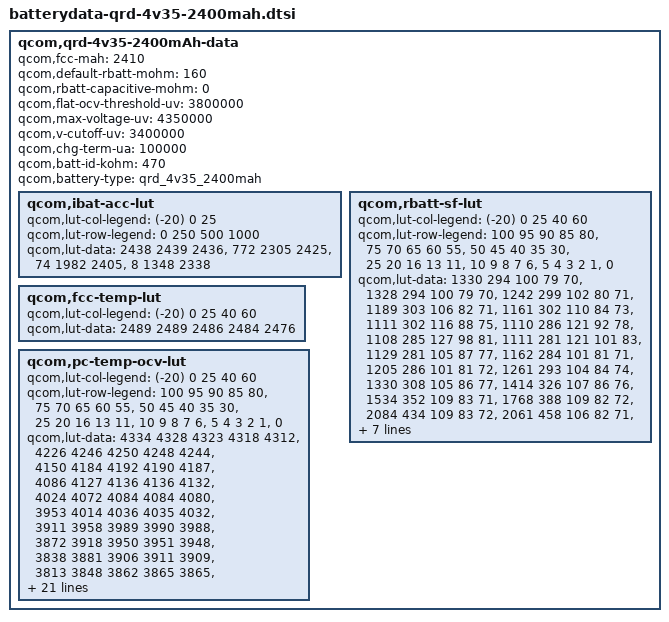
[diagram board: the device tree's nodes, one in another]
/* Copyright (c) 2013, The Linux Foundation. All rights reserved.
 *
 * This program is free software; you can redistribute it and/or modify
 * it under the terms of the GNU General Public License version 2 and
 * only version 2 as published by the Free Software Foundation.
 *
 * This program is distributed in the hope that it will be useful,
 * but WITHOUT ANY WARRANTY; without even the implied warranty of
 * MERCHANTABILITY or FITNESS FOR A PARTICULAR PURPOSE.  See the
 * GNU General Public License for more details.
 */

qcom,qrd-4v35-2400mAh-data {
	qcom,fcc-mah = <2410>;
	qcom,default-rbatt-mohm = <160>;
	qcom,rbatt-capacitive-mohm = <0>;
	qcom,flat-ocv-threshold-uv = <3800000>;
	qcom,max-voltage-uv = <4350000>;
	qcom,v-cutoff-uv = <3400000>;
	qcom,chg-term-ua = <100000>;
	qcom,batt-id-kohm = <470>;
	qcom,battery-type = "qrd_4v35_2400mah";


	qcom,ibat-acc-lut {
		qcom,lut-col-legend = <(-20) 0 25>;
		qcom,lut-row-legend = <0 250 500 1000>;
		qcom,lut-data = <2438 2439 2436>,
				<772 2305 2425>,
				<74 1982 2405>,
				<8 1348 2338>;

	};

	qcom,rbatt-sf-lut {
		qcom,lut-col-legend = <(-20) 0 25 40 60>;
		qcom,lut-row-legend = <100 95 90 85 80>,
				      <75 70 65 60 55>, 
				      <50 45 40 35 30>,
				      <25 20 16 13 11>,
				      <10 9 8 7 6>, 
				      <5 4 3 2 1>,
				      <0>;

		qcom,lut-data = <1330 294 100 79 70>,
				<1328 294 100 79 70>,
				<1242 299 102 80 71>,
				<1189 303 106 82 71>,
				<1161 302 110 84 73>,
				<1111 302 116 88 75>,
				<1110 286 121 92 78>,
				<1108 285 127 98 81>,
				<1111 281 121 101 83>,
				<1129 281 105 87 77>,
				<1162 284 101 81 71>,
				<1205 286 101 81 72>,
				<1261 293 104 84 74>,
				<1330 308 105 86 77>,
				<1414 326 107 86 76>,
				<1534 352 109 83 71>,
				<1768 388 109 82 72>,
				<2084 434 109 83 72>,
				<2061 458 106 82 71>,
				<2350 490 108 82 72>,
				<2564 520 109 82 72>,
				<2858 554 112 85 74>,
				<3199 594 118 87 76>,
				<3651 646 123 91 78>,
				<4219 704 131 94 78>,
				<5028 769 132 91 75>,
				<6214 849 131 90 76>,
				<8123 965 139 92 79>,
				<11718 1208 156 101 85>,
				<20686 2415 265 174 111>,
				<41372 4830 530 349 222>;
	};

	qcom,fcc-temp-lut {
		qcom,lut-col-legend = <(-20) 0 25 40 60>;
		qcom,lut-data = <2489 2489 2486 2484 2476>;
	};

	qcom,pc-temp-ocv-lut {
		qcom,lut-col-legend = <(-20) 0 25 40 60>;
		qcom,lut-row-legend = <100 95 90 85 80>,
				      <75 70 65 60 55>, 
				      <50 45 40 35 30>,
				      <25 20 16 13 11>,
				      <10 9 8 7 6>, 
				      <5 4 3 2 1>,
				      <0>;
		qcom,lut-data = <4334 4328 4323 4318 4312>,
				<4226 4246 4250 4248 4244>,
				<4150 4184 4192 4190 4187>,
				<4086 4127 4136 4136 4132>,
				<4024 4072 4084 4084 4080>,
				<3953 4014 4036 4035 4032>,
				<3911 3958 3989 3990 3988>,
				<3872 3918 3950 3951 3948>,
				<3838 3881 3906 3911 3909>,
				<3813 3848 3862 3865 3865>,
				<3795 3822 3832 3832 3831>,
				<3780 3800 3809 3810 3809>,
				<3767 3782 3792 3792 3791>,
				<3752 3770 3777 3778 3776>,
				<3736 3758 3766 3763 3758>,
				<3716 3743 3754 3748 3735>,
				<3693 3724 3736 3728 3714>,
				<3672 3707 3712 3705 3692>,
				<3653 3694 3688 3681 3669>,
				<3638 3684 3680 3673 3662>,
				<3627 3678 3677 3671 3660>,
				<3616 3672 3674 3669 3658>,
				<3602 3666 3672 3666 3656>,
				<3586 3658 3668 3662 3652>,
				<3566 3644 3660 3656 3642>,
				<3544 3620 3640 3632 3614>,
				<3514 3578 3595 3586 3567>,
				<3472 3515 3530 3522 3503>,
				<3408 3418 3441 3435 3416>,
				<3287 3257 3305 3302 3282>,
				<3000 3000 3000 3000 3000>;
	};
};
